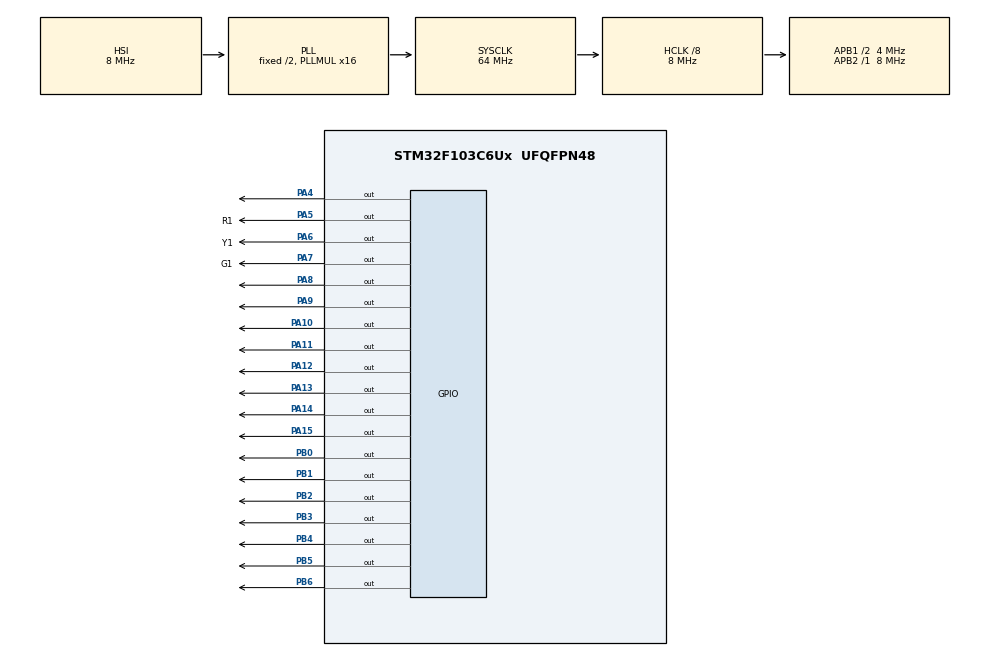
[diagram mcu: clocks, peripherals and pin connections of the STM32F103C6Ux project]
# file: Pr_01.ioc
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Mcu.Family=STM32F1
Mcu.Name=STM32F103C6Ux
Mcu.Package=UFQFPN48
NVIC.PriorityGroup=NVIC_PRIORITYGROUP_4
PA10.Signal=GPIO_Output
PA11.Signal=GPIO_Output
PA12.Signal=GPIO_Output
PA13.Signal=GPIO_Output
PA14.Signal=GPIO_Output
PA15.Signal=GPIO_Output
PA4.Signal=GPIO_Output
PA5.GPIO_Label=R1
PA5.Signal=GPIO_Output
PA6.GPIO_Label=Y1
PA6.Signal=GPIO_Output
PA7.GPIO_Label=G1
PA7.Signal=GPIO_Output
PA8.Signal=GPIO_Output
PA9.Signal=GPIO_Output
PB0.PinState=GPIO_PIN_SET
PB0.Signal=GPIO_Output
PB1.PinState=GPIO_PIN_SET
PB1.Signal=GPIO_Output
PB2.PinState=GPIO_PIN_SET
PB2.Signal=GPIO_Output
PB3.PinState=GPIO_PIN_SET
PB3.Signal=GPIO_Output
PB4.PinState=GPIO_PIN_SET
PB4.Signal=GPIO_Output
PB5.PinState=GPIO_PIN_SET
PB5.Signal=GPIO_Output
PB6.PinState=GPIO_PIN_SET
PB6.Signal=GPIO_Output
PD0-OSC_IN.Mode=HSE-External-Oscillator
PD0-OSC_IN.Signal=RCC_OSC_IN
PD1-OSC_OUT.Mode=HSE-External-Oscillator
PD1-OSC_OUT.Signal=RCC_OSC_OUT
ProjectManager.HeapSize=0x200
ProjectManager.StackSize=0x400
ProjectManager.TargetToolchain=STM32CubeIDE
RCC.AHBCLKDivider=RCC_SYSCLK_DIV8
RCC.AHBFreq_Value=8000000
RCC.APB1CLKDivider=RCC_HCLK_DIV2
RCC.APB1Freq_Value=4000000
RCC.APB1TimFreq_Value=8000000
RCC.APB2Freq_Value=8000000
RCC.APB2TimFreq_Value=8000000
RCC.HCLKFreq_Value=8000000
RCC.PLLMUL=RCC_PLL_MUL16
RCC.SYSCLKFreq_VALUE=64000000
RCC.SYSCLKSource=RCC_SYSCLKSOURCE_PLLCLK
RCC.USBFreq_Value=64000000
VP_SYS_VS_ND.Mode=No_Debug
board=custom

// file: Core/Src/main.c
/* USER CODE BEGIN Header */
/**
  ******************************************************************************
  * @file           : main.c
  * @brief          : Main program body
  ******************************************************************************
  * @attention
  *
  * Copyright (c) 2024 STMicroelectronics.
  * All rights reserved.
  *
  * This software is licensed under terms that can be found in the LICENSE file
  * in the root directory of this software component.
  * If no LICENSE file comes with this software, it is provided AS-IS.
  *
  ******************************************************************************
  */
/* USER CODE END Header */
#include "main.h"

/* USER CODE BEGIN Includes */
#include "user.h"
/* USER CODE END Includes */

void SystemClock_Config(void);
static void MX_GPIO_Init(void);

int main(void)
{

  /* MCU Configuration--------------------------------------------------------*/

  /* Reset of all peripherals, Initializes the Flash interface and the Systick. */
  HAL_Init();

  /* Configure the system clock */
  SystemClock_Config();

  /* Initialize all configured peripherals */
  MX_GPIO_Init();

  /* Infinite loop */
  /* USER CODE BEGIN WHILE */

  while (1)
  {
	  //Ex_04
	  //Led_run(5, 2, 3);

	  //Ex_05
	  //control_traffic_light(5, 2, 3);

	  //Ex_06
	  check();
    /* USER CODE END WHILE */

  }
}

void SystemClock_Config(void)
{
  RCC_OscInitTypeDef RCC_OscInitStruct = {0};
  RCC_ClkInitTypeDef RCC_ClkInitStruct = {0};

  /** Initializes the RCC Oscillators according to the specified parameters
  * in the RCC_OscInitTypeDef structure.
  */
  RCC_OscInitStruct.OscillatorType = RCC_OSCILLATORTYPE_HSI;
  RCC_OscInitStruct.HSIState = RCC_HSI_ON;
  RCC_OscInitStruct.HSICalibrationValue = RCC_HSICALIBRATION_DEFAULT;
  RCC_OscInitStruct.PLL.PLLState = RCC_PLL_ON;
  RCC_OscInitStruct.PLL.PLLSource = RCC_PLLSOURCE_HSI_DIV2;
  RCC_OscInitStruct.PLL.PLLMUL = RCC_PLL_MUL16;
  if (HAL_RCC_OscConfig(&RCC_OscInitStruct) != HAL_OK)
  {
    Error_Handler();
  }

  /** Initializes the CPU, AHB and APB buses clocks
  */
  RCC_ClkInitStruct.ClockType = RCC_CLOCKTYPE_HCLK|RCC_CLOCKTYPE_SYSCLK
                              |RCC_CLOCKTYPE_PCLK1|RCC_CLOCKTYPE_PCLK2;
  RCC_ClkInitStruct.SYSCLKSource = RCC_SYSCLKSOURCE_PLLCLK;
  RCC_ClkInitStruct.AHBCLKDivider = RCC_SYSCLK_DIV8;
  RCC_ClkInitStruct.APB1CLKDivider = RCC_HCLK_DIV2;
  RCC_ClkInitStruct.APB2CLKDivider = RCC_HCLK_DIV1;

  if (HAL_RCC_ClockConfig(&RCC_ClkInitStruct, FLASH_LATENCY_2) != HAL_OK)
  {
    Error_Handler();
  }
}

static void MX_GPIO_Init(void)
{
  GPIO_InitTypeDef GPIO_InitStruct = {0};

  /* GPIO Ports Clock Enable */
  __HAL_RCC_GPIOD_CLK_ENABLE();
  __HAL_RCC_GPIOA_CLK_ENABLE();
  __HAL_RCC_GPIOB_CLK_ENABLE();

  /*Configure GPIO pin Output Level */
  HAL_GPIO_WritePin(GPIOA, GPIO_PIN_4|R1_Pin|Y1_Pin|G1_Pin
                          |GPIO_PIN_8|GPIO_PIN_9|GPIO_PIN_10|GPIO_PIN_11
                          |GPIO_PIN_12|GPIO_PIN_13|GPIO_PIN_14|GPIO_PIN_15, GPIO_PIN_RESET);

  /*Configure GPIO pin Output Level */
  HAL_GPIO_WritePin(GPIOB, GPIO_PIN_0|GPIO_PIN_1|GPIO_PIN_2|GPIO_PIN_3
                          |GPIO_PIN_4|GPIO_PIN_5|GPIO_PIN_6, GPIO_PIN_SET);

  /*Configure GPIO pins : PA4 R1_Pin Y1_Pin G1_Pin
                           PA8 PA9 PA10 PA11
                           PA12 PA13 PA14 PA15 */
  GPIO_InitStruct.Pin = GPIO_PIN_4|R1_Pin|Y1_Pin|G1_Pin
                          |GPIO_PIN_8|GPIO_PIN_9|GPIO_PIN_10|GPIO_PIN_11
                          |GPIO_PIN_12|GPIO_PIN_13|GPIO_PIN_14|GPIO_PIN_15;
  GPIO_InitStruct.Mode = GPIO_MODE_OUTPUT_PP;
  GPIO_InitStruct.Pull = GPIO_NOPULL;
  GPIO_InitStruct.Speed = GPIO_SPEED_FREQ_LOW;
  HAL_GPIO_Init(GPIOA, &GPIO_InitStruct);

  /*Configure GPIO pins : PB0 PB1 PB2 PB3
                           PB4 PB5 PB6 */
  GPIO_InitStruct.Pin = GPIO_PIN_0|GPIO_PIN_1|GPIO_PIN_2|GPIO_PIN_3
                          |GPIO_PIN_4|GPIO_PIN_5|GPIO_PIN_6;
  GPIO_InitStruct.Mode = GPIO_MODE_OUTPUT_PP;
  GPIO_InitStruct.Pull = GPIO_NOPULL;
  GPIO_InitStruct.Speed = GPIO_SPEED_FREQ_LOW;
  HAL_GPIO_Init(GPIOB, &GPIO_InitStruct);

}

void Error_Handler(void)
{
  __disable_irq();
  while (1)
  {
  }
}
